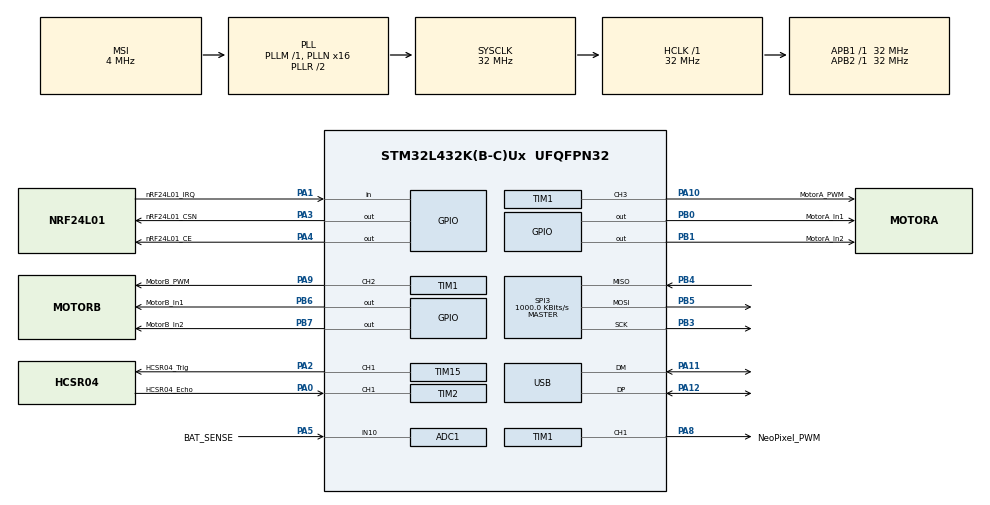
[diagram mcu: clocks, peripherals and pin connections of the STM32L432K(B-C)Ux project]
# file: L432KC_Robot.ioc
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ADC1.Channel-4\#ChannelRegularConversion=ADC_CHANNEL_10
ADC1.ClockPrescaler=ADC_CLOCK_ASYNC_DIV128
ADC1.ContinuousConvMode=ENABLE
ADC1.DMAContinuousRequests=ENABLE
ADC1.EnableRegularConversion=ENABLE
ADC1.NbrOfConversionFlag=1
ADC1.OffsetNumber-4\#ChannelRegularConversion=ADC_OFFSET_NONE
ADC1.Rank-4\#ChannelRegularConversion=1
ADC1.SamplingTime-4\#ChannelRegularConversion=ADC_SAMPLETIME_2CYCLES_5
ADC1.master=1
Dma.ADC1.0.Direction=DMA_PERIPH_TO_MEMORY
Dma.ADC1.0.Instance=DMA1_Channel1
Dma.ADC1.0.MemDataAlignment=DMA_MDATAALIGN_HALFWORD
Dma.ADC1.0.MemInc=DMA_MINC_ENABLE
Dma.ADC1.0.Mode=DMA_CIRCULAR
Dma.ADC1.0.PeriphDataAlignment=DMA_PDATAALIGN_HALFWORD
Dma.ADC1.0.PeriphInc=DMA_PINC_DISABLE
Dma.ADC1.0.Priority=DMA_PRIORITY_LOW
Dma.Request0=ADC1
Dma.Request1=TIM1_CH1
Dma.TIM1_CH1.1.Direction=DMA_MEMORY_TO_PERIPH
Dma.TIM1_CH1.1.Instance=DMA1_Channel2
Dma.TIM1_CH1.1.MemDataAlignment=DMA_MDATAALIGN_BYTE
Dma.TIM1_CH1.1.MemInc=DMA_MINC_ENABLE
Dma.TIM1_CH1.1.Mode=DMA_NORMAL
Dma.TIM1_CH1.1.PeriphDataAlignment=DMA_PDATAALIGN_HALFWORD
Dma.TIM1_CH1.1.PeriphInc=DMA_PINC_DISABLE
Dma.TIM1_CH1.1.Priority=DMA_PRIORITY_LOW
Mcu.Family=STM32L4
Mcu.Name=STM32L432K(B-C)Ux
Mcu.Package=UFQFPN32
NVIC.DMA1_Channel1_IRQn=true\:0\:0\:false\:false\:true\:false\:true\:true
NVIC.DMA1_Channel2_IRQn=true\:0\:0\:false\:false\:true\:false\:true\:true
NVIC.PriorityGroup=NVIC_PRIORITYGROUP_4
NVIC.TIM1_UP_TIM16_IRQn=true\:0\:0\:false\:false\:true\:true\:true\:true
NVIC.TIM2_IRQn=true\:0\:0\:false\:false\:true\:true\:true\:true
NVIC.TIM6_DAC_IRQn=true\:0\:0\:false\:false\:true\:true\:true\:true
NVIC.TIM7_IRQn=true\:0\:0\:false\:false\:true\:true\:true\:true
NVIC.USB_IRQn=true\:0\:0\:false\:false\:true\:false\:true\:true
PA0.GPIO_Label=HCSR04_Echo
PA0.Signal=S_TIM2_CH1
PA1.GPIO_Label=nRF24L01_IRQ
PA1.Signal=GPIO_Input
PA10.GPIO_Label=MotorA_PWM
PA10.Signal=S_TIM1_CH3
PA11.Mode=Device
PA11.Signal=USB_DM
PA12.Mode=Device
PA12.Signal=USB_DP
PA13\ (JTMS-SWDIO).Mode=Serial_Wire
PA13\ (JTMS-SWDIO).Signal=SYS_JTMS-SWDIO
PA14\ (JTCK-SWCLK).Mode=Serial_Wire
PA14\ (JTCK-SWCLK).Signal=SYS_JTCK-SWCLK
PA2.GPIO_Label=HCSR04_Trig
PA2.Signal=S_TIM15_CH1
PA3.GPIO_Label=nRF24L01_CSN
PA3.Signal=GPIO_Output
PA4.GPIO_Label=nRF24L01_CE
PA4.Signal=GPIO_Output
PA5.GPIO_Label=BAT_SENSE
PA5.Signal=ADCx_IN10
PA8.GPIO_Label=NeoPixel_PWM
PA8.Signal=S_TIM1_CH1
PA9.GPIO_Label=MotorB_PWM
PA9.Signal=S_TIM1_CH2
PB0.GPIO_Label=MotorA_In1
PB0.Signal=GPIO_Output
PB1.GPIO_Label=MotorA_In2
PB1.Signal=GPIO_Output
PB3\ (JTDO-TRACESWO).Mode=Full_Duplex_Master
PB3\ (JTDO-TRACESWO).Signal=SPI3_SCK
PB4\ (NJTRST).Mode=Full_Duplex_Master
PB4\ (NJTRST).Signal=SPI3_MISO
PB5.Mode=Full_Duplex_Master
PB5.Signal=SPI3_MOSI
PB6.GPIO_Label=MotorB_In1
PB6.Signal=GPIO_Output
PB7.GPIO_Label=MotorB_In2
PB7.Signal=GPIO_Output
ProjectManager.HeapSize=0x200
ProjectManager.StackSize=0x400
ProjectManager.TargetToolchain=STM32CubeIDE
RCC.ADCFreq_Value=48000000
RCC.AHBFreq_Value=32000000
RCC.APB1Freq_Value=32000000
RCC.APB1TimFreq_Value=32000000
RCC.APB2Freq_Value=32000000
RCC.APB2TimFreq_Value=32000000
RCC.CortexFreq_Value=32000000
RCC.HCLKFreq_Value=32000000
RCC.HSE_VALUE=8000000
RCC.HSI16_VALUE=16000000
RCC.HSI48_VALUE=48000000
RCC.HSI_VALUE=16000000
RCC.LSE_VALUE=32768
RCC.MSI_VALUE=4000000
RCC.PLLMUL=RCC_PLLMUL_4
RCC.PLLN=16
RCC.PLLSAI1N=24
RCC.SYSCLKFreq_VALUE=32000000
RCC.SYSCLKSource=RCC_SYSCLKSOURCE_PLLCLK
RCC.USBFreq_Value=48000000
RCC.VCOOutputFreq_Value=64000000
SH.ADCx_IN10.0=ADC1_IN10,IN10-Single-Ended
SH.S_TIM15_CH1.0=TIM15_CH1,PWM Generation1 CH1
SH.S_TIM1_CH1.0=TIM1_CH1,PWM Generation1 CH1
SH.S_TIM1_CH2.0=TIM1_CH2,PWM Generation2 CH2
SH.S_TIM1_CH3.0=TIM1_CH3,PWM Generation3 CH3
SH.S_TIM2_CH1.0=TIM2_CH1,Input_Capture1_from_TI1
SPI3.BaudRatePrescaler=SPI_BAUDRATEPRESCALER_32
SPI3.CalculateBaudRate=1000.0 KBits/s
SPI3.DataSize=SPI_DATASIZE_8BIT
SPI3.Direction=SPI_DIRECTION_2LINES
SPI3.Mode=SPI_MODE_MASTER
SPI3.VirtualType=VM_MASTER
TIM1.AutoReloadPreload=TIM_AUTORELOAD_PRELOAD_ENABLE
TIM1.Channel-PWM\ Generation1\ CH1=TIM_CHANNEL_1
TIM1.Channel-PWM\ Generation2\ CH2=TIM_CHANNEL_2
TIM1.Channel-PWM\ Generation3\ CH3=TIM_CHANNEL_3
TIM1.CounterMode=TIM_COUNTERMODE_UP
TIM1.Period=40-1
TIM1.Prescaler=1-1
TIM1.RepetitionCounter=0
TIM15.Channel-PWM\ Generation1\ CH1=TIM_CHANNEL_1
TIM15.OC1Preload_PWM=ENABLE
TIM15.OCFastMode_PWM-PWM\ Generation1\ CH1=TIM_OCFAST_ENABLE
TIM15.OCMode_PWM-PWM\ Generation1\ CH1=TIM_OCMODE_PWM1
TIM15.OCPolarity_1=TIM_OCPOLARITY_LOW
TIM15.Period=20-1
TIM15.Prescaler=32-1
TIM15.Pulse-PWM\ Generation1\ CH1=5-1
TIM2.Channel-Input_Capture1_from_TI1=TIM_CHANNEL_1
TIM2.ICPolarity_CH1=TIM_INPUTCHANNELPOLARITY_BOTHEDGE
TIM2.Prescaler=32-1
TIM6.Period=1920
TIM6.Prescaler=1000
TIM7.AutoReloadPreload=TIM_AUTORELOAD_PRELOAD_DISABLE
TIM7.Period=1000-1
TIM7.Prescaler=32000-1
USB_DEVICE.CLASS_NAME_FS=CDC
USB_DEVICE.VirtualMode=Cdc
USB_DEVICE.VirtualModeFS=Cdc_FS
VP_TIM15_VS_OPM.Mode=OPM_bit
VP_TIM6_VS_ClockSourceINT.Mode=Enable_Timer
VP_TIM7_VS_ClockSourceINT.Mode=Enable_Timer
VP_USB_DEVICE_VS_USB_DEVICE_CDC_FS.Mode=CDC_FS
board=NUCLEO-L432KC

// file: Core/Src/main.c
/* USER CODE BEGIN Header */
/**
  ******************************************************************************
  * @file           : main.c
  * @brief          : Main program body
  ******************************************************************************
  * @attention
  *
  * Copyright (c) 2026 STMicroelectronics.
  * All rights reserved.
  *
  * This software is licensed under terms that can be found in the LICENSE file
  * in the root directory of this software component.
  * If no LICENSE file comes with this software, it is provided AS-IS.
  *
  ******************************************************************************
  */
/* USER CODE END Header */
#include "main.h"
#include "usb_device.h"

/* USER CODE BEGIN Includes */
#include "robot.h"
/* USER CODE END Includes */

ADC_HandleTypeDef hadc1;
DMA_HandleTypeDef hdma_adc1;

SPI_HandleTypeDef hspi3;

TIM_HandleTypeDef htim1;
TIM_HandleTypeDef htim2;
TIM_HandleTypeDef htim6;
TIM_HandleTypeDef htim7;
TIM_HandleTypeDef htim15;
DMA_HandleTypeDef hdma_tim1_ch1;

void SystemClock_Config(void);
void PeriphCommonClock_Config(void);
static void MX_GPIO_Init(void);
static void MX_DMA_Init(void);
static void MX_ADC1_Init(void);
static void MX_TIM1_Init(void);
static void MX_TIM7_Init(void);
static void MX_TIM6_Init(void);
static void MX_TIM15_Init(void);
static void MX_TIM2_Init(void);
static void MX_SPI3_Init(void);

/* USER CODE BEGIN 0 */
//This function retargets the stdout to the USB peripheral
//so that printf will work normally (except it needs to be
//viewed from a serial terminal).
#include "usbd_cdc_if.h"
int _write(int file, char* ptr, int len)
{
	CDC_Transmit_FS((uint8_t*)ptr, len);
	return len;
}
/* USER CODE END 0 */

int main(void)
{

  /* MCU Configuration--------------------------------------------------------*/

  /* Reset of all peripherals, Initializes the Flash interface and the Systick. */
  HAL_Init();

  /* Configure the system clock */
  SystemClock_Config();

  /* Configure the peripherals common clocks */
  PeriphCommonClock_Config();

  /* Initialize all configured peripherals */
  MX_GPIO_Init();
  MX_DMA_Init();
  MX_ADC1_Init();
  MX_TIM1_Init();
  MX_TIM7_Init();
  MX_TIM6_Init();
  MX_TIM15_Init();
  MX_TIM2_Init();
  MX_USB_DEVICE_Init();
  MX_SPI3_Init();

  /* Infinite loop */
  /* USER CODE BEGIN WHILE */
  //This is the actual main loop, the while(1) loop below is not used as the main loop.
  robot_main();
  while (1)
  {
    /* USER CODE END WHILE */

  }
}

void SystemClock_Config(void)
{
  RCC_OscInitTypeDef RCC_OscInitStruct = {0};
  RCC_ClkInitTypeDef RCC_ClkInitStruct = {0};

  /** Configure the main internal regulator output voltage
  */
  if (HAL_PWREx_ControlVoltageScaling(PWR_REGULATOR_VOLTAGE_SCALE1) != HAL_OK)
  {
    Error_Handler();
  }

  /** Initializes the RCC Oscillators according to the specified parameters
  * in the RCC_OscInitTypeDef structure.
  */
  RCC_OscInitStruct.OscillatorType = RCC_OSCILLATORTYPE_MSI;
  RCC_OscInitStruct.MSIState = RCC_MSI_ON;
  RCC_OscInitStruct.MSICalibrationValue = 0;
  RCC_OscInitStruct.MSIClockRange = RCC_MSIRANGE_6;
  RCC_OscInitStruct.PLL.PLLState = RCC_PLL_ON;
  RCC_OscInitStruct.PLL.PLLSource = RCC_PLLSOURCE_MSI;
  RCC_OscInitStruct.PLL.PLLM = 1;
  RCC_OscInitStruct.PLL.PLLN = 16;
  RCC_OscInitStruct.PLL.PLLP = RCC_PLLP_DIV7;
  RCC_OscInitStruct.PLL.PLLQ = RCC_PLLQ_DIV2;
  RCC_OscInitStruct.PLL.PLLR = RCC_PLLR_DIV2;
  if (HAL_RCC_OscConfig(&RCC_OscInitStruct) != HAL_OK)
  {
    Error_Handler();
  }

  /** Initializes the CPU, AHB and APB buses clocks
  */
  RCC_ClkInitStruct.ClockType = RCC_CLOCKTYPE_HCLK|RCC_CLOCKTYPE_SYSCLK
                              |RCC_CLOCKTYPE_PCLK1|RCC_CLOCKTYPE_PCLK2;
  RCC_ClkInitStruct.SYSCLKSource = RCC_SYSCLKSOURCE_PLLCLK;
  RCC_ClkInitStruct.AHBCLKDivider = RCC_SYSCLK_DIV1;
  RCC_ClkInitStruct.APB1CLKDivider = RCC_HCLK_DIV1;
  RCC_ClkInitStruct.APB2CLKDivider = RCC_HCLK_DIV1;

  if (HAL_RCC_ClockConfig(&RCC_ClkInitStruct, FLASH_LATENCY_1) != HAL_OK)
  {
    Error_Handler();
  }
}

void PeriphCommonClock_Config(void)
{
  RCC_PeriphCLKInitTypeDef PeriphClkInit = {0};

  /** Initializes the peripherals clock
  */
  PeriphClkInit.PeriphClockSelection = RCC_PERIPHCLK_USB|RCC_PERIPHCLK_ADC;
  PeriphClkInit.AdcClockSelection = RCC_ADCCLKSOURCE_PLLSAI1;
  PeriphClkInit.UsbClockSelection = RCC_USBCLKSOURCE_PLLSAI1;
  PeriphClkInit.PLLSAI1.PLLSAI1Source = RCC_PLLSOURCE_MSI;
  PeriphClkInit.PLLSAI1.PLLSAI1M = 1;
  PeriphClkInit.PLLSAI1.PLLSAI1N = 24;
  PeriphClkInit.PLLSAI1.PLLSAI1P = RCC_PLLP_DIV7;
  PeriphClkInit.PLLSAI1.PLLSAI1Q = RCC_PLLQ_DIV2;
  PeriphClkInit.PLLSAI1.PLLSAI1R = RCC_PLLR_DIV2;
  PeriphClkInit.PLLSAI1.PLLSAI1ClockOut = RCC_PLLSAI1_48M2CLK|RCC_PLLSAI1_ADC1CLK;
  if (HAL_RCCEx_PeriphCLKConfig(&PeriphClkInit) != HAL_OK)
  {
    Error_Handler();
  }
}

static void MX_ADC1_Init(void)
{

  ADC_ChannelConfTypeDef sConfig = {0};

  /** Common config
  */
  hadc1.Instance = ADC1;
  hadc1.Init.ClockPrescaler = ADC_CLOCK_ASYNC_DIV128;
  hadc1.Init.Resolution = ADC_RESOLUTION_12B;
  hadc1.Init.DataAlign = ADC_DATAALIGN_RIGHT;
  hadc1.Init.ScanConvMode = ADC_SCAN_DISABLE;
  hadc1.Init.EOCSelection = ADC_EOC_SINGLE_CONV;
  hadc1.Init.LowPowerAutoWait = DISABLE;
  hadc1.Init.ContinuousConvMode = ENABLE;
  hadc1.Init.NbrOfConversion = 1;
  hadc1.Init.DiscontinuousConvMode = DISABLE;
  hadc1.Init.ExternalTrigConv = ADC_SOFTWARE_START;
  hadc1.Init.ExternalTrigConvEdge = ADC_EXTERNALTRIGCONVEDGE_NONE;
  hadc1.Init.DMAContinuousRequests = ENABLE;
  hadc1.Init.Overrun = ADC_OVR_DATA_PRESERVED;
  hadc1.Init.OversamplingMode = DISABLE;
  if (HAL_ADC_Init(&hadc1) != HAL_OK)
  {
    Error_Handler();
  }

  /** Configure Regular Channel
  */
  sConfig.Channel = ADC_CHANNEL_10;
  sConfig.Rank = ADC_REGULAR_RANK_1;
  sConfig.SamplingTime = ADC_SAMPLETIME_2CYCLES_5;
  sConfig.SingleDiff = ADC_SINGLE_ENDED;
  sConfig.OffsetNumber = ADC_OFFSET_NONE;
  sConfig.Offset = 0;
  if (HAL_ADC_ConfigChannel(&hadc1, &sConfig) != HAL_OK)
  {
    Error_Handler();
  }

}

static void MX_SPI3_Init(void)
{

  /* SPI3 parameter configuration*/
  hspi3.Instance = SPI3;
  hspi3.Init.Mode = SPI_MODE_MASTER;
  hspi3.Init.Direction = SPI_DIRECTION_2LINES;
  hspi3.Init.DataSize = SPI_DATASIZE_8BIT;
  hspi3.Init.CLKPolarity = SPI_POLARITY_LOW;
  hspi3.Init.CLKPhase = SPI_PHASE_1EDGE;
  hspi3.Init.NSS = SPI_NSS_SOFT;
  hspi3.Init.BaudRatePrescaler = SPI_BAUDRATEPRESCALER_32;
  hspi3.Init.FirstBit = SPI_FIRSTBIT_MSB;
  hspi3.Init.TIMode = SPI_TIMODE_DISABLE;
  hspi3.Init.CRCCalculation = SPI_CRCCALCULATION_DISABLE;
  hspi3.Init.CRCPolynomial = 7;
  hspi3.Init.CRCLength = SPI_CRC_LENGTH_DATASIZE;
  hspi3.Init.NSSPMode = SPI_NSS_PULSE_ENABLE;
  if (HAL_SPI_Init(&hspi3) != HAL_OK)
  {
    Error_Handler();
  }

}

static void MX_TIM1_Init(void)
{

  TIM_MasterConfigTypeDef sMasterConfig = {0};
  TIM_OC_InitTypeDef sConfigOC = {0};
  TIM_BreakDeadTimeConfigTypeDef sBreakDeadTimeConfig = {0};

  htim1.Instance = TIM1;
  htim1.Init.Prescaler = 1-1;
  htim1.Init.CounterMode = TIM_COUNTERMODE_UP;
  htim1.Init.Period = 40-1;
  htim1.Init.ClockDivision = TIM_CLOCKDIVISION_DIV1;
  htim1.Init.RepetitionCounter = 0;
  htim1.Init.AutoReloadPreload = TIM_AUTORELOAD_PRELOAD_ENABLE;
  if (HAL_TIM_PWM_Init(&htim1) != HAL_OK)
  {
    Error_Handler();
  }
  sMasterConfig.MasterOutputTrigger = TIM_TRGO_RESET;
  sMasterConfig.MasterOutputTrigger2 = TIM_TRGO2_RESET;
  sMasterConfig.MasterSlaveMode = TIM_MASTERSLAVEMODE_DISABLE;
  if (HAL_TIMEx_MasterConfigSynchronization(&htim1, &sMasterConfig) != HAL_OK)
  {
    Error_Handler();
  }
  sConfigOC.OCMode = TIM_OCMODE_PWM1;
  sConfigOC.Pulse = 0;
  sConfigOC.OCPolarity = TIM_OCPOLARITY_HIGH;
  sConfigOC.OCNPolarity = TIM_OCNPOLARITY_HIGH;
  sConfigOC.OCFastMode = TIM_OCFAST_DISABLE;
  sConfigOC.OCIdleState = TIM_OCIDLESTATE_RESET;
  sConfigOC.OCNIdleState = TIM_OCNIDLESTATE_RESET;
  if (HAL_TIM_PWM_ConfigChannel(&htim1, &sConfigOC, TIM_CHANNEL_1) != HAL_OK)
  {
    Error_Handler();
  }
  if (HAL_TIM_PWM_ConfigChannel(&htim1, &sConfigOC, TIM_CHANNEL_2) != HAL_OK)
  {
    Error_Handler();
  }
  if (HAL_TIM_PWM_ConfigChannel(&htim1, &sConfigOC, TIM_CHANNEL_3) != HAL_OK)
  {
    Error_Handler();
  }
  sBreakDeadTimeConfig.OffStateRunMode = TIM_OSSR_DISABLE;
  sBreakDeadTimeConfig.OffStateIDLEMode = TIM_OSSI_DISABLE;
  sBreakDeadTimeConfig.LockLevel = TIM_LOCKLEVEL_OFF;
  sBreakDeadTimeConfig.DeadTime = 0;
  sBreakDeadTimeConfig.BreakState = TIM_BREAK_DISABLE;
  sBreakDeadTimeConfig.BreakPolarity = TIM_BREAKPOLARITY_HIGH;
  sBreakDeadTimeConfig.BreakFilter = 0;
  sBreakDeadTimeConfig.Break2State = TIM_BREAK2_DISABLE;
  sBreakDeadTimeConfig.Break2Polarity = TIM_BREAK2POLARITY_HIGH;
  sBreakDeadTimeConfig.Break2Filter = 0;
  sBreakDeadTimeConfig.AutomaticOutput = TIM_AUTOMATICOUTPUT_DISABLE;
  if (HAL_TIMEx_ConfigBreakDeadTime(&htim1, &sBreakDeadTimeConfig) != HAL_OK)
  {
    Error_Handler();
  }
  HAL_TIM_MspPostInit(&htim1);

}

static void MX_TIM2_Init(void)
{

  TIM_MasterConfigTypeDef sMasterConfig = {0};
  TIM_IC_InitTypeDef sConfigIC = {0};

  htim2.Instance = TIM2;
  htim2.Init.Prescaler = 32-1;
  htim2.Init.CounterMode = TIM_COUNTERMODE_UP;
  htim2.Init.Period = 4294967295;
  htim2.Init.ClockDivision = TIM_CLOCKDIVISION_DIV1;
  htim2.Init.AutoReloadPreload = TIM_AUTORELOAD_PRELOAD_DISABLE;
  if (HAL_TIM_IC_Init(&htim2) != HAL_OK)
  {
    Error_Handler();
  }
  sMasterConfig.MasterOutputTrigger = TIM_TRGO_RESET;
  sMasterConfig.MasterSlaveMode = TIM_MASTERSLAVEMODE_DISABLE;
  if (HAL_TIMEx_MasterConfigSynchronization(&htim2, &sMasterConfig) != HAL_OK)
  {
    Error_Handler();
  }
  sConfigIC.ICPolarity = TIM_INPUTCHANNELPOLARITY_BOTHEDGE;
  sConfigIC.ICSelection = TIM_ICSELECTION_DIRECTTI;
  sConfigIC.ICPrescaler = TIM_ICPSC_DIV1;
  sConfigIC.ICFilter = 0;
  if (HAL_TIM_IC_ConfigChannel(&htim2, &sConfigIC, TIM_CHANNEL_1) != HAL_OK)
  {
    Error_Handler();
  }

}

static void MX_TIM6_Init(void)
{

  TIM_MasterConfigTypeDef sMasterConfig = {0};

  htim6.Instance = TIM6;
  htim6.Init.Prescaler = 1000;
  htim6.Init.CounterMode = TIM_COUNTERMODE_UP;
  htim6.Init.Period = 1920;
  htim6.Init.AutoReloadPreload = TIM_AUTORELOAD_PRELOAD_DISABLE;
  if (HAL_TIM_Base_Init(&htim6) != HAL_OK)
  {
    Error_Handler();
  }
  sMasterConfig.MasterOutputTrigger = TIM_TRGO_RESET;
  sMasterConfig.MasterSlaveMode = TIM_MASTERSLAVEMODE_DISABLE;
  if (HAL_TIMEx_MasterConfigSynchronization(&htim6, &sMasterConfig) != HAL_OK)
  {
    Error_Handler();
  }

}

static void MX_TIM7_Init(void)
{

  TIM_MasterConfigTypeDef sMasterConfig = {0};

  htim7.Instance = TIM7;
  htim7.Init.Prescaler = 32000-1;
  htim7.Init.CounterMode = TIM_COUNTERMODE_UP;
  htim7.Init.Period = 1000-1;
  htim7.Init.AutoReloadPreload = TIM_AUTORELOAD_PRELOAD_DISABLE;
  if (HAL_TIM_Base_Init(&htim7) != HAL_OK)
  {
    Error_Handler();
  }
  sMasterConfig.MasterOutputTrigger = TIM_TRGO_RESET;
  sMasterConfig.MasterSlaveMode = TIM_MASTERSLAVEMODE_DISABLE;
  if (HAL_TIMEx_MasterConfigSynchronization(&htim7, &sMasterConfig) != HAL_OK)
  {
    Error_Handler();
  }

}

static void MX_TIM15_Init(void)
{

  TIM_MasterConfigTypeDef sMasterConfig = {0};
  TIM_OC_InitTypeDef sConfigOC = {0};
  TIM_BreakDeadTimeConfigTypeDef sBreakDeadTimeConfig = {0};

  htim15.Instance = TIM15;
  htim15.Init.Prescaler = 32-1;
  htim15.Init.CounterMode = TIM_COUNTERMODE_UP;
  htim15.Init.Period = 20-1;
  htim15.Init.ClockDivision = TIM_CLOCKDIVISION_DIV1;
  htim15.Init.RepetitionCounter = 0;
  htim15.Init.AutoReloadPreload = TIM_AUTORELOAD_PRELOAD_DISABLE;
  if (HAL_TIM_PWM_Init(&htim15) != HAL_OK)
  {
    Error_Handler();
  }
  if (HAL_TIM_OnePulse_Init(&htim15, TIM_OPMODE_SINGLE) != HAL_OK)
  {
    Error_Handler();
  }
  sMasterConfig.MasterOutputTrigger = TIM_TRGO_RESET;
  sMasterConfig.MasterSlaveMode = TIM_MASTERSLAVEMODE_DISABLE;
  if (HAL_TIMEx_MasterConfigSynchronization(&htim15, &sMasterConfig) != HAL_OK)
  {
    Error_Handler();
  }
  sConfigOC.OCMode = TIM_OCMODE_PWM1;
  sConfigOC.Pulse = 5-1;
  sConfigOC.OCPolarity = TIM_OCPOLARITY_LOW;
  sConfigOC.OCNPolarity = TIM_OCNPOLARITY_HIGH;
  sConfigOC.OCFastMode = TIM_OCFAST_ENABLE;
  sConfigOC.OCIdleState = TIM_OCIDLESTATE_RESET;
  sConfigOC.OCNIdleState = TIM_OCNIDLESTATE_RESET;
  if (HAL_TIM_PWM_ConfigChannel(&htim15, &sConfigOC, TIM_CHANNEL_1) != HAL_OK)
  {
    Error_Handler();
  }
  sBreakDeadTimeConfig.OffStateRunMode = TIM_OSSR_DISABLE;
  sBreakDeadTimeConfig.OffStateIDLEMode = TIM_OSSI_DISABLE;
  sBreakDeadTimeConfig.LockLevel = TIM_LOCKLEVEL_OFF;
  sBreakDeadTimeConfig.DeadTime = 0;
  sBreakDeadTimeConfig.BreakState = TIM_BREAK_DISABLE;
  sBreakDeadTimeConfig.BreakPolarity = TIM_BREAKPOLARITY_HIGH;
  sBreakDeadTimeConfig.AutomaticOutput = TIM_AUTOMATICOUTPUT_DISABLE;
  if (HAL_TIMEx_ConfigBreakDeadTime(&htim15, &sBreakDeadTimeConfig) != HAL_OK)
  {
    Error_Handler();
  }
  HAL_TIM_MspPostInit(&htim15);

}

static void MX_DMA_Init(void)
{

  /* DMA controller clock enable */
  __HAL_RCC_DMA1_CLK_ENABLE();

  /* DMA interrupt init */
  /* DMA1_Channel1_IRQn interrupt configuration */
  HAL_NVIC_SetPriority(DMA1_Channel1_IRQn, 0, 0);
  HAL_NVIC_EnableIRQ(DMA1_Channel1_IRQn);
  /* DMA1_Channel2_IRQn interrupt configuration */
  HAL_NVIC_SetPriority(DMA1_Channel2_IRQn, 0, 0);
  HAL_NVIC_EnableIRQ(DMA1_Channel2_IRQn);

}

static void MX_GPIO_Init(void)
{
  GPIO_InitTypeDef GPIO_InitStruct = {0};

  /* GPIO Ports Clock Enable */
  __HAL_RCC_GPIOA_CLK_ENABLE();
  __HAL_RCC_GPIOB_CLK_ENABLE();

  /*Configure GPIO pin Output Level */
  HAL_GPIO_WritePin(GPIOA, nRF24L01_CSN_Pin|nRF24L01_CE_Pin, GPIO_PIN_RESET);

  /*Configure GPIO pin Output Level */
  HAL_GPIO_WritePin(GPIOB, MotorA_In1_Pin|MotorA_In2_Pin|MotorB_In1_Pin|MotorB_In2_Pin, GPIO_PIN_RESET);

  /*Configure GPIO pin : nRF24L01_IRQ_Pin */
  GPIO_InitStruct.Pin = nRF24L01_IRQ_Pin;
  GPIO_InitStruct.Mode = GPIO_MODE_INPUT;
  GPIO_InitStruct.Pull = GPIO_NOPULL;
  HAL_GPIO_Init(nRF24L01_IRQ_GPIO_Port, &GPIO_InitStruct);

  /*Configure GPIO pins : nRF24L01_CSN_Pin nRF24L01_CE_Pin */
  GPIO_InitStruct.Pin = nRF24L01_CSN_Pin|nRF24L01_CE_Pin;
  GPIO_InitStruct.Mode = GPIO_MODE_OUTPUT_PP;
  GPIO_InitStruct.Pull = GPIO_NOPULL;
  GPIO_InitStruct.Speed = GPIO_SPEED_FREQ_LOW;
  HAL_GPIO_Init(GPIOA, &GPIO_InitStruct);

  /*Configure GPIO pins : MotorA_In1_Pin MotorA_In2_Pin MotorB_In1_Pin MotorB_In2_Pin */
  GPIO_InitStruct.Pin = MotorA_In1_Pin|MotorA_In2_Pin|MotorB_In1_Pin|MotorB_In2_Pin;
  GPIO_InitStruct.Mode = GPIO_MODE_OUTPUT_PP;
  GPIO_InitStruct.Pull = GPIO_NOPULL;
  GPIO_InitStruct.Speed = GPIO_SPEED_FREQ_LOW;
  HAL_GPIO_Init(GPIOB, &GPIO_InitStruct);

}

void Error_Handler(void)
{
  __disable_irq();
  while (1)
  {
  }
}
